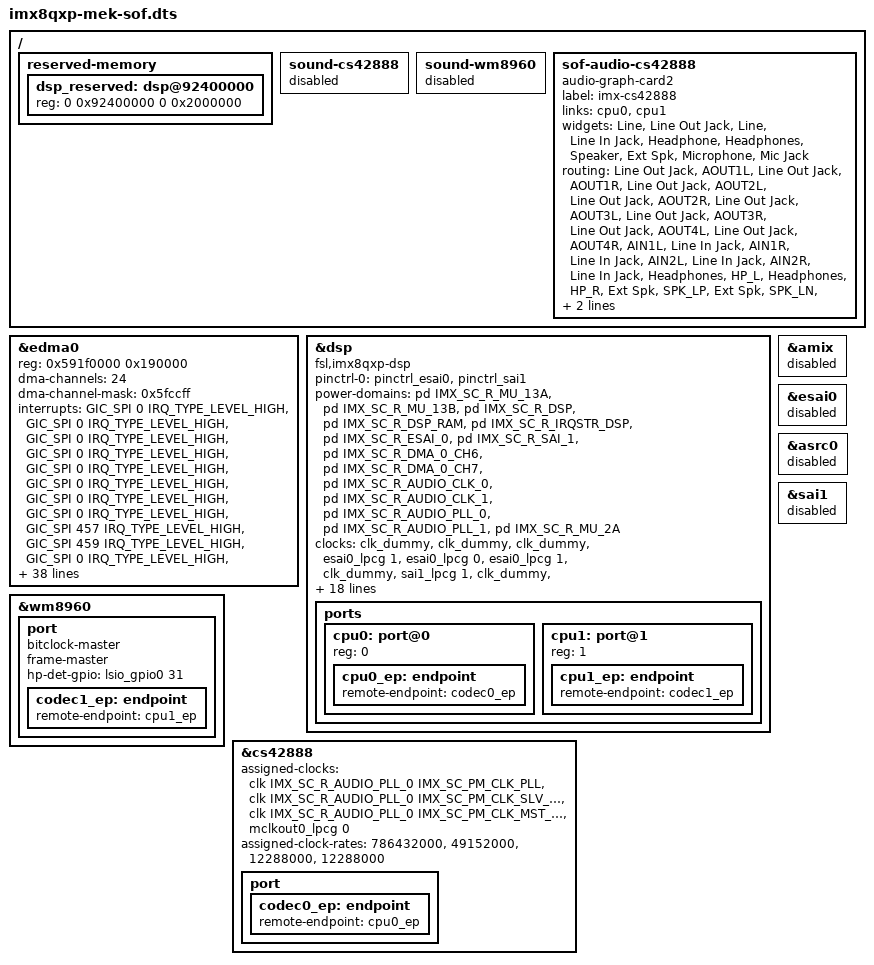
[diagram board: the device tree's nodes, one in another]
// SPDX-License-Identifier: GPL-2.0+
// Copyright NXP 2022

#include "imx8qxp-mek-rpmsg.dts"

/delete-node/ &dsp_reserved_heap;
/delete-node/ &dsp_vdev0vring0;
/delete-node/ &dsp_vdev0vring1;
/delete-node/ &dsp_vdev0buffer;

/ {
	reserved-memory {
		dsp_reserved: dsp@92400000 {
			reg = <0 0x92400000 0 0x2000000>;
		};
	};

	sound-cs42888 {
		status = "disabled";
	};

	sound-wm8960 {
		status = "disabled";
	};

	sof-audio-cs42888 {
		compatible = "audio-graph-card2";
		label = "imx-cs42888";
		links = <&cpu0 &cpu1>;
		widgets =
			"Line", "Line Out Jack",
			"Line", "Line In Jack",
			"Headphone", "Headphones",
			"Speaker", "Ext Spk",
			"Microphone", "Mic Jack";

		routing =
			"Line Out Jack", "AOUT1L",
			"Line Out Jack", "AOUT1R",
			"Line Out Jack", "AOUT2L",
			"Line Out Jack", "AOUT2R",
			"Line Out Jack", "AOUT3L",
			"Line Out Jack", "AOUT3R",
			"Line Out Jack", "AOUT4L",
			"Line Out Jack", "AOUT4R",
			"AIN1L", "Line In Jack",
			"AIN1R", "Line In Jack",
			"AIN2L", "Line In Jack",
			"AIN2R", "Line In Jack",
			"Headphones", "HP_L",
			"Headphones", "HP_R",
			"Ext Spk", "SPK_LP",
			"Ext Spk", "SPK_LN",
			"Ext Spk", "SPK_RP",
			"Ext Spk", "SPK_RN",
			"LINPUT1", "Mic Jack",
			"Mic Jack", "MICB";
		status = "okay";
	};
};

&edma0 {
	reg = <0x591f0000 0x190000>;
	dma-channels = <24>;
	dma-channel-mask = <0x5fccff>;
	interrupts = <GIC_SPI 0   IRQ_TYPE_LEVEL_HIGH>, /* 0 asrc 0 */
		     <GIC_SPI 0   IRQ_TYPE_LEVEL_HIGH>, /* 1 */
		     <GIC_SPI 0   IRQ_TYPE_LEVEL_HIGH>, /* 2 */
		     <GIC_SPI 0   IRQ_TYPE_LEVEL_HIGH>, /* 3 */
		     <GIC_SPI 0   IRQ_TYPE_LEVEL_HIGH>, /* 4 */
		     <GIC_SPI 0   IRQ_TYPE_LEVEL_HIGH>, /* 5 */
		     <GIC_SPI 0   IRQ_TYPE_LEVEL_HIGH>, /* 6 esai0 */
		     <GIC_SPI 0   IRQ_TYPE_LEVEL_HIGH>, /* 7 */
		     <GIC_SPI 457 IRQ_TYPE_LEVEL_HIGH>, /* 8 spdif0 */
		     <GIC_SPI 459 IRQ_TYPE_LEVEL_HIGH>, /* 9 */
		     <GIC_SPI 0   IRQ_TYPE_LEVEL_HIGH>, /* 10 unused */
		     <GIC_SPI 0   IRQ_TYPE_LEVEL_HIGH>, /* 11 unused */
		     <GIC_SPI 315 IRQ_TYPE_LEVEL_HIGH>, /* 12 sai0 */
		     <GIC_SPI 315 IRQ_TYPE_LEVEL_HIGH>, /* 13 */
		     <GIC_SPI 0   IRQ_TYPE_LEVEL_HIGH>, /* 14 sai1 */
		     <GIC_SPI 0   IRQ_TYPE_LEVEL_HIGH>, /* 15 */
		     <GIC_SPI 0   IRQ_TYPE_LEVEL_HIGH>, /* 16 sai2 */
		     <GIC_SPI 0   IRQ_TYPE_LEVEL_HIGH>, /* 17 sai3 */
		     <GIC_SPI 0   IRQ_TYPE_LEVEL_HIGH>, /* 18 unused */
		     <GIC_SPI 0   IRQ_TYPE_LEVEL_HIGH>, /* 19 unused */
		     <GIC_SPI 0   IRQ_TYPE_LEVEL_HIGH>, /* 20 unused */
		     <GIC_SPI 391 IRQ_TYPE_LEVEL_HIGH>, /* 21 */
		     <GIC_SPI 0   IRQ_TYPE_LEVEL_HIGH>, /* 22 unused */
		     <GIC_SPI 393 IRQ_TYPE_LEVEL_HIGH>, /* 23 */
		     <GIC_SPI 369 IRQ_TYPE_LEVEL_HIGH>;
	power-domains = <&pd IMX_SC_R_DMA_0_CH0>,
			<&pd IMX_SC_R_DMA_0_CH1>,
			<&pd IMX_SC_R_DMA_0_CH2>,
			<&pd IMX_SC_R_DMA_0_CH3>,
			<&pd IMX_SC_R_DMA_0_CH4>,
			<&pd IMX_SC_R_DMA_0_CH5>,
			<&pd IMX_SC_R_DMA_0_CH6>,
			<&pd IMX_SC_R_DMA_0_CH7>,
			<&pd IMX_SC_R_DMA_0_CH8>,
			<&pd IMX_SC_R_DMA_0_CH9>,
			<&pd IMX_SC_R_DMA_0_CH10>,
			<&pd IMX_SC_R_DMA_0_CH11>,
			<&pd IMX_SC_R_DMA_0_CH12>,
			<&pd IMX_SC_R_DMA_0_CH13>,
			<&pd IMX_SC_R_DMA_0_CH14>,
			<&pd IMX_SC_R_DMA_0_CH15>,
			<&pd IMX_SC_R_DMA_0_CH16>,
			<&pd IMX_SC_R_DMA_0_CH17>,
			<&pd IMX_SC_R_DMA_0_CH18>,
			<&pd IMX_SC_R_DMA_0_CH19>,
			<&pd IMX_SC_R_DMA_0_CH20>,
			<&pd IMX_SC_R_DMA_0_CH21>,
			<&pd IMX_SC_R_DMA_0_CH22>,
			<&pd IMX_SC_R_DMA_0_CH23>;
};

&dsp {
	#sound-dai-cells = <1>;
	compatible = "fsl,imx8qxp-dsp";
	pinctrl-names = "default";
	pinctrl-0 = <&pinctrl_esai0>, <&pinctrl_sai1>;

	power-domains = <&pd IMX_SC_R_MU_13A>,
			<&pd IMX_SC_R_MU_13B>,
			<&pd IMX_SC_R_DSP>,
			<&pd IMX_SC_R_DSP_RAM>,
			<&pd IMX_SC_R_IRQSTR_DSP>,
			<&pd IMX_SC_R_ESAI_0>,
			<&pd IMX_SC_R_SAI_1>,
			<&pd IMX_SC_R_DMA_0_CH6>,
			<&pd IMX_SC_R_DMA_0_CH7>,
			<&pd IMX_SC_R_AUDIO_CLK_0>,
			<&pd IMX_SC_R_AUDIO_CLK_1>,
			<&pd IMX_SC_R_AUDIO_PLL_0>,
			<&pd IMX_SC_R_AUDIO_PLL_1>,
			<&pd IMX_SC_R_MU_2A>;

		clocks = <&clk_dummy>, <&clk_dummy>, <&clk_dummy>, <&esai0_lpcg 1>, <&esai0_lpcg 0>,  <&esai0_lpcg 1>,
			<&clk_dummy>, <&sai1_lpcg 1>, <&clk_dummy>, <&clk_dummy>,
			<&sai1_lpcg 0>, <&clk_dummy>, <&clk_dummy>;
		clock-names = "ipg", "ocram", "core", "esai0_core", "esai0_extal", "esai0_fsys", "esai0_spba",
				"sai1_bus", "sai1_mclk0", "sai1_mclk1", "sai1_mclk2", "sai1_mclk3";
		assigned-clocks = <&acm IMX_ADMA_ACM_ESAI0_MCLK_SEL>,
			<&acm IMX_ADMA_ACM_SAI1_MCLK_SEL>,
			<&clk IMX_SC_R_AUDIO_PLL_0 IMX_SC_PM_CLK_PLL>,
			<&clk IMX_SC_R_AUDIO_PLL_0 IMX_SC_PM_CLK_MISC0>,
			<&clk IMX_SC_R_AUDIO_PLL_0 IMX_SC_PM_CLK_MISC1>,
			<&esai0_lpcg 0>;
		assigned-clock-parents = <&aud_pll_div0_lpcg 0>;
		assigned-clock-rates = <0>, <0>, <786432000>, <49152000>, <12288000>, <49152000>;

	mbox-names = "txdb0", "txdb1", "rxdb0", "rxdb1";
	mboxes = <&lsio_mu13 2 0>,
		<&lsio_mu13 2 1>,
		<&lsio_mu13 3 0>,
		<&lsio_mu13 3 1>;
	memory-region = <&dsp_reserved>;
	/delete-property/ firmware-name;

	reg = <0x596e8000 0x88000>;
	tplg-name = "sof-imx8-wm8960-cs42888.tplg";
	machine-drv-name = "asoc-audio-graph-card2";

	status = "okay";

	ports {
		#address-cells = <1>;
		#size-cells = <0>;

		cpu0: port@0 { reg = <0>; cpu0_ep: endpoint { remote-endpoint = <&codec0_ep>; }; };
		cpu1: port@1 { reg = <1>; cpu1_ep: endpoint { remote-endpoint = <&codec1_ep>; }; };
	};
};

&amix {
	status = "disabled";
};

&esai0 {
	status = "disabled";
};

&asrc0 {
	status = "disabled";
};

&sai1 {
	status = "disabled";
};

&wm8960 {
	status = "okay";

	port {
		bitclock-master;
		frame-master;
		hp-det-gpio = <&lsio_gpio0 31 GPIO_ACTIVE_HIGH>;
		codec1_ep: endpoint { remote-endpoint = <&cpu1_ep>; };
	};
};

&cs42888 {
	assigned-clocks = <&clk IMX_SC_R_AUDIO_PLL_0 IMX_SC_PM_CLK_PLL>,
			  <&clk IMX_SC_R_AUDIO_PLL_0 IMX_SC_PM_CLK_SLV_BUS>,
			  <&clk IMX_SC_R_AUDIO_PLL_0 IMX_SC_PM_CLK_MST_BUS>,
			  <&mclkout0_lpcg 0>;
	assigned-clock-rates = <786432000>, <49152000>, <12288000>, <12288000>;
	status = "okay";

	port { codec0_ep: endpoint { remote-endpoint = <&cpu0_ep>; }; };
};
